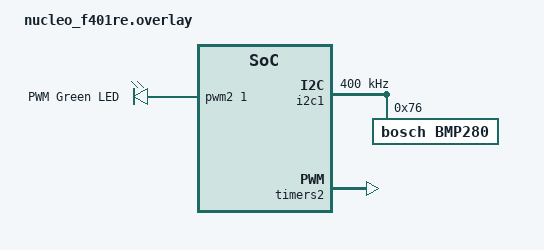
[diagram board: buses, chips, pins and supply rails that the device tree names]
&i2c1 {
    status = "okay";
    clock-frequency = <I2C_BITRATE_FAST>;

    bmp280: bmp280@76 {
        compatible = "bosch,bmp280";
        reg = <0x76>;
        status = "okay";
    };
};

&timers2 {
    status = "okay";
    st,prescaler = <10>;

    pwm2: pwm {
        status = "okay";
        pinctrl-0 = <&tim2_ch1_pa5>;
        pinctrl-names = "default";
    };
};

/ {
    pwmleds {
        compatible = "pwm-leds";
        pwm_led_0: pwm_led_0 {
            pwms = <&pwm2 1 PWM_MSEC(20) PWM_POLARITY_NORMAL>;
            label = "PWM Green LED";
        };
    };

    aliases {
        pwm-led0 = &pwm_led_0;
    };
};
